# iom480ae register map
Registers are 32-bit, access not given, no defined reset value unless marked. A register's access mark holds for its fields unless they carry their own. Addresses are absolute; registers are grouped by the start of their names; [hi:lo] are bit positions.

## USPI1
0x400D1000 USPI1_USPI_CTL
  [2:0] FUNMODE
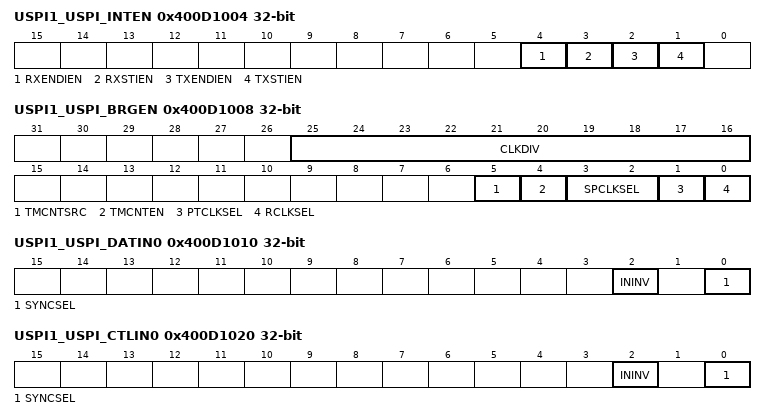
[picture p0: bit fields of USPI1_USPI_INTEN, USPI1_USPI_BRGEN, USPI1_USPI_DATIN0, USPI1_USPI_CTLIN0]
0x400D1004 USPI1_USPI_INTEN
  [4] RXENDIEN, [3] RXSTIEN, [2] TXENDIEN, [1] TXSTIEN
0x400D1008 USPI1_USPI_BRGEN
  [25:16] CLKDIV, [5] TMCNTSRC, [4] TMCNTEN, [3:2] SPCLKSEL, [1] PTCLKSEL, [0] RCLKSEL
0x400D1010 USPI1_USPI_DATIN0
  [2] ININV, [0] SYNCSEL
0x400D1020 USPI1_USPI_CTLIN0
  [2] ININV, [0] SYNCSEL
0x400D1028 USPI1_USPI_CLKIN
  [0] SYNCSEL
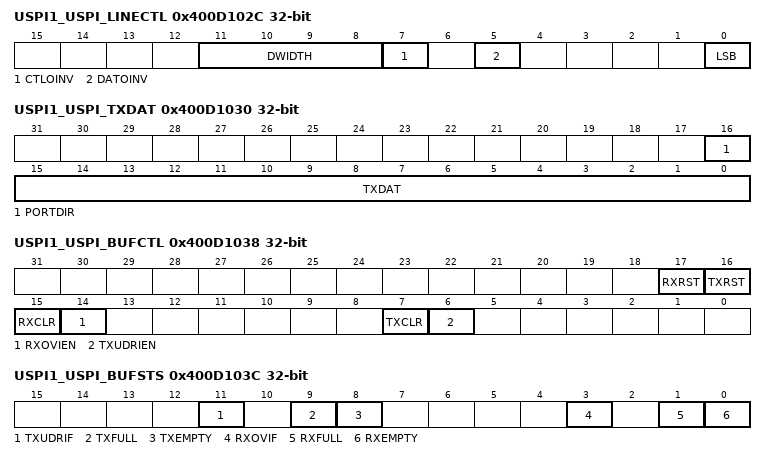
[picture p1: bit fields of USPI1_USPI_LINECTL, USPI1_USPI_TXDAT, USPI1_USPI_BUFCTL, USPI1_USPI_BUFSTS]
0x400D102C USPI1_USPI_LINECTL
  [11:8] DWIDTH, [7] CTLOINV, [5] DATOINV, [0] LSB
0x400D1030 USPI1_USPI_TXDAT
  [16] PORTDIR, [15:0] TXDAT
0x400D1034 USPI1_USPI_RXDAT
  [15:0] RXDAT
0x400D1038 USPI1_USPI_BUFCTL
  [17] RXRST, [16] TXRST, [15] RXCLR, [14] RXOVIEN, [7] TXCLR, [6] TXUDRIEN
0x400D103C USPI1_USPI_BUFSTS
  [11] TXUDRIF, [9] TXFULL, [8] TXEMPTY, [3] RXOVIF, [1] RXFULL, [0] RXEMPTY
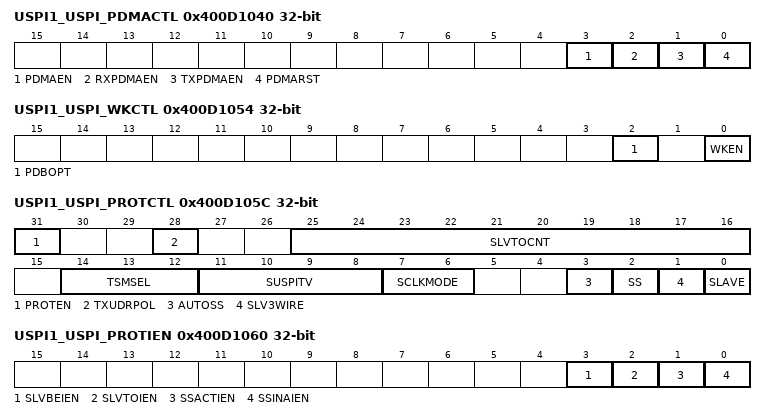
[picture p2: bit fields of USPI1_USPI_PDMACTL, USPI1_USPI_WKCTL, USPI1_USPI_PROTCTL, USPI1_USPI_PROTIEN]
0x400D1040 USPI1_USPI_PDMACTL
  [3] PDMAEN, [2] RXPDMAEN, [1] TXPDMAEN, [0] PDMARST
0x400D1054 USPI1_USPI_WKCTL
  [2] PDBOPT, [0] WKEN
0x400D1058 USPI1_USPI_WKSTS
  [0] WKF
0x400D105C USPI1_USPI_PROTCTL
  [31] PROTEN, [28] TXUDRPOL, [25:16] SLVTOCNT, [14:12] TSMSEL, [11:8] SUSPITV, [7:6] SCLKMODE, [3] AUTOSS, [2] SS, [1] SLV3WIRE, [0] SLAVE
0x400D1060 USPI1_USPI_PROTIEN
  [3] SLVBEIEN, [2] SLVTOIEN, [1] SSACTIEN, [0] SSINAIEN
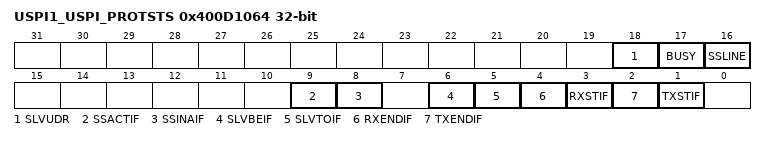
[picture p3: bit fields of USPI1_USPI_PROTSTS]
0x400D1064 USPI1_USPI_PROTSTS
  [18] SLVUDR, [17] BUSY, [16] SSLINE, [9] SSACTIF, [8] SSINAIF, [6] SLVBEIF, [5] SLVTOIF, [4] RXENDIF, [3] RXSTIF, [2] TXENDIF, [1] TXSTIF

## UI2C0
0x400D0000 UI2C0_UI2C_CTL
  [2:0] FUNMODE
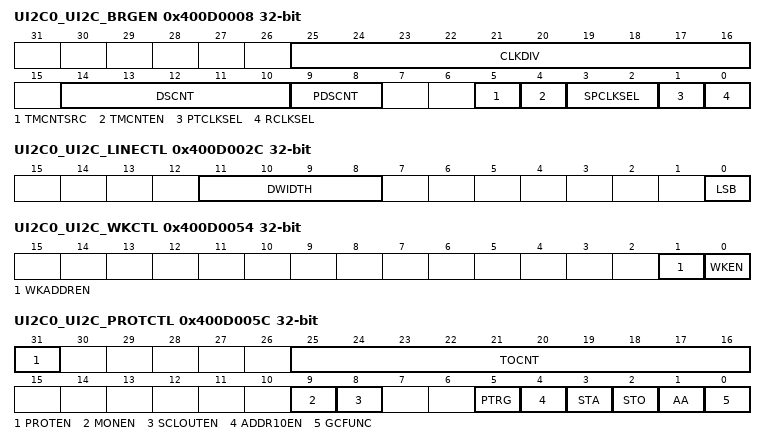
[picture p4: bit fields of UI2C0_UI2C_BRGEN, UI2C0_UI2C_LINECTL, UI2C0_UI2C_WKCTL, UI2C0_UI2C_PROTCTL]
0x400D0008 UI2C0_UI2C_BRGEN
  [25:16] CLKDIV, [14:10] DSCNT, [9:8] PDSCNT, [5] TMCNTSRC, [4] TMCNTEN, [3:2] SPCLKSEL, [1] PTCLKSEL, [0] RCLKSEL
0x400D002C UI2C0_UI2C_LINECTL
  [11:8] DWIDTH, [0] LSB
0x400D0030 UI2C0_UI2C_TXDAT
  [15:0] TXDAT
0x400D0034 UI2C0_UI2C_RXDAT
  [15:0] RXDAT
0x400D0044 UI2C0_UI2C_DEVADDR0
  [9:0] DEVADDR
0x400D0048 UI2C0_UI2C_DEVADDR1
  [9:0] DEVADDR
0x400D004C UI2C0_UI2C_ADDRMSK0
  [9:0] ADDRMSK
0x400D0050 UI2C0_UI2C_ADDRMSK1
  [9:0] ADDRMSK
0x400D0054 UI2C0_UI2C_WKCTL
  [1] WKADDREN, [0] WKEN
0x400D0058 UI2C0_UI2C_WKSTS
  [0] WKF
0x400D005C UI2C0_UI2C_PROTCTL
  [31] PROTEN, [25:16] TOCNT, [9] MONEN, [8] SCLOUTEN, [5] PTRG, [4] ADDR10EN, [3] STA, [2] STO, [1] AA, [0] GCFUNC
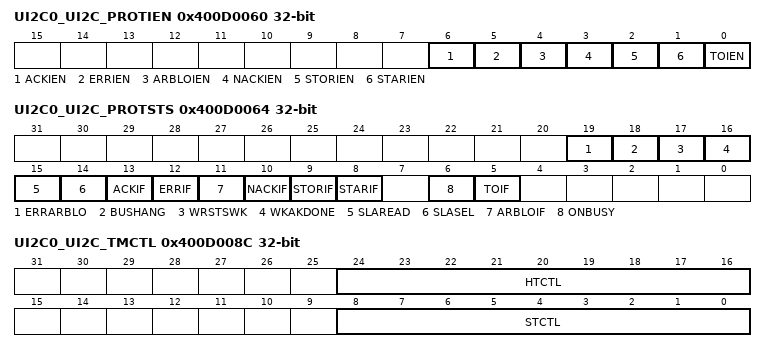
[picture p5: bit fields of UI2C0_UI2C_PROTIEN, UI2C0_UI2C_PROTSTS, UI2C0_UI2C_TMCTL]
0x400D0060 UI2C0_UI2C_PROTIEN
  [6] ACKIEN, [5] ERRIEN, [4] ARBLOIEN, [3] NACKIEN, [2] STORIEN, [1] STARIEN, [0] TOIEN
0x400D0064 UI2C0_UI2C_PROTSTS
  [19] ERRARBLO, [18] BUSHANG, [17] WRSTSWK, [16] WKAKDONE, [15] SLAREAD, [14] SLASEL, [13] ACKIF, [12] ERRIF, [11] ARBLOIF, [10] NACKIF, [9] STORIF, [8] STARIF, [6] ONBUSY, [5] TOIF
0x400D008C UI2C0_UI2C_TMCTL
  [24:16] HTCTL, [8:0] STCTL

## UI2C1
0x400D1000 UI2C1_UI2C_CTL
  [2:0] FUNMODE
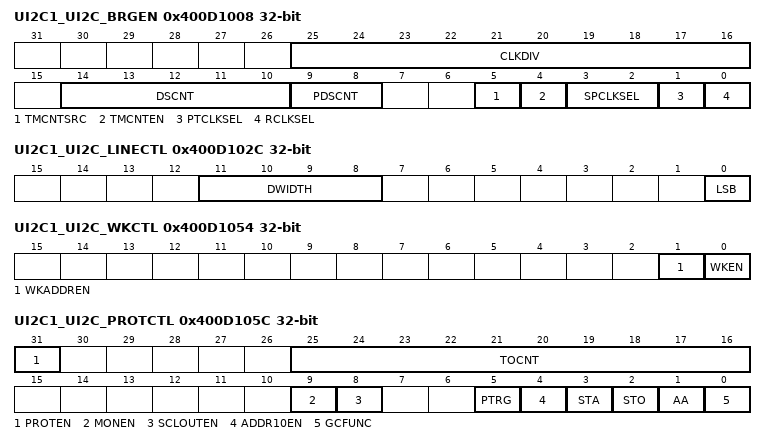
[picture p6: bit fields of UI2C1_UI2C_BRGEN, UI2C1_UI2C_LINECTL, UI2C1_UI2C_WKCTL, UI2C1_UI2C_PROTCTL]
0x400D1008 UI2C1_UI2C_BRGEN
  [25:16] CLKDIV, [14:10] DSCNT, [9:8] PDSCNT, [5] TMCNTSRC, [4] TMCNTEN, [3:2] SPCLKSEL, [1] PTCLKSEL, [0] RCLKSEL
0x400D102C UI2C1_UI2C_LINECTL
  [11:8] DWIDTH, [0] LSB
0x400D1030 UI2C1_UI2C_TXDAT
  [15:0] TXDAT
0x400D1034 UI2C1_UI2C_RXDAT
  [15:0] RXDAT
0x400D1044 UI2C1_UI2C_DEVADDR0
  [9:0] DEVADDR
0x400D1048 UI2C1_UI2C_DEVADDR1
  [9:0] DEVADDR
0x400D104C UI2C1_UI2C_ADDRMSK0
  [9:0] ADDRMSK
0x400D1050 UI2C1_UI2C_ADDRMSK1
  [9:0] ADDRMSK
0x400D1054 UI2C1_UI2C_WKCTL
  [1] WKADDREN, [0] WKEN
0x400D1058 UI2C1_UI2C_WKSTS
  [0] WKF
0x400D105C UI2C1_UI2C_PROTCTL
  [31] PROTEN, [25:16] TOCNT, [9] MONEN, [8] SCLOUTEN, [5] PTRG, [4] ADDR10EN, [3] STA, [2] STO, [1] AA, [0] GCFUNC
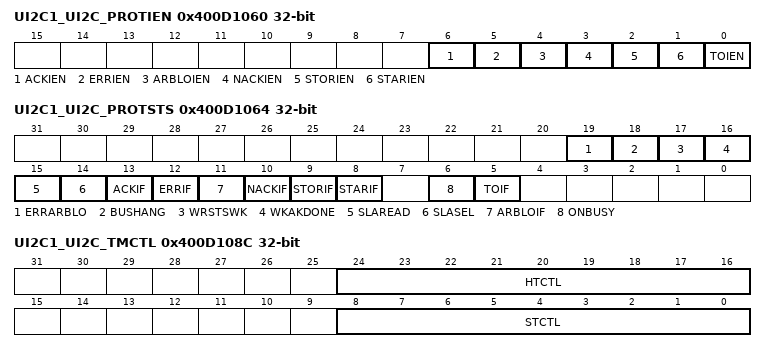
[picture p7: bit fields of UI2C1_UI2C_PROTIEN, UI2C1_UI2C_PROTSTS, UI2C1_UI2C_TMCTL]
0x400D1060 UI2C1_UI2C_PROTIEN
  [6] ACKIEN, [5] ERRIEN, [4] ARBLOIEN, [3] NACKIEN, [2] STORIEN, [1] STARIEN, [0] TOIEN
0x400D1064 UI2C1_UI2C_PROTSTS
  [19] ERRARBLO, [18] BUSHANG, [17] WRSTSWK, [16] WKAKDONE, [15] SLAREAD, [14] SLASEL, [13] ACKIF, [12] ERRIF, [11] ARBLOIF, [10] NACKIF, [9] STORIF, [8] STARIF, [6] ONBUSY, [5] TOIF
0x400D108C UI2C1_UI2C_TMCTL
  [24:16] HTCTL, [8:0] STCTL
